# ATSAM4LC8C device description
Architecture: CORTEX-M4; Family: SAM4; Series: SAM4L
Registers are 32-bit, read-write, reset 0x0 unless marked. A register's access mark holds for its fields unless they carry their own. Offsets are from the block's base; [hi:lo] are bit positions; 'fields as' and 'values as' point back to an identical list.

## IISC — Inter-IC Sound (I2S) Controller
Instances: IISC 0x40004000
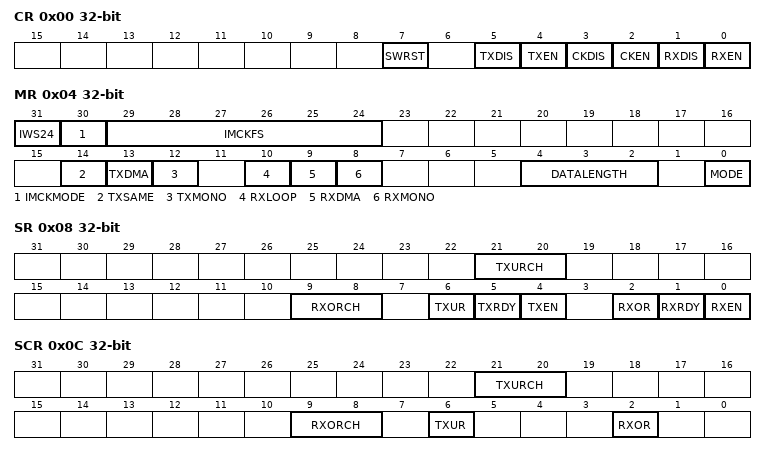
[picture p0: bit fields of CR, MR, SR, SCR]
0x00 CR wo reset not defined — Control Register
  [7] SWRST — Software Reset
    0=OFF (No effect); 1=ON (Performs a software reset. Has priority on any other bit in CR)
  [5] TXDIS — Transmit Disable
    0=OFF (No effect); 1=ON (Disables Data Transmit)
  [4] TXEN — Transmit Enable
    0=OFF (No effect); 1=ON (Enables Data Transmit if TXDIS is not set)
  [3] CKDIS — Clocks Disable
    0=OFF (No effect); 1=ON (Disables clocks)
  [2] CKEN — Clocks Enable
    0=OFF (No effect); 1=ON (Enables clocks if CKDIS is not set)
  [1] RXDIS — Receive Disable
    0=OFF (No effect); 1=ON (Disables Data Receive)
  [0] RXEN — Receive Enable
    0=OFF (No effect); 1=ON (Enables Data Receive if RXDIS is not set)
0x04 MR — Mode Register
  [31] IWS24 — IWS Data Slot Width
    0=IWS Data Slot is 32-bit wide for DATALENGTH=18/20/24-bit; 1=IWS Data Slot is 24-bit wide for DATALENGTH=18/20/24-bit
  [30] IMCKMODE — Master Clock Mode
    0=NO_IMCK (No IMCK generated); 1=IMCK (IMCK generated)
  [29:24] IMCKFS — Master Clock to fs Ratio
    0=16 fs; 1=32 fs; 3=64 fs; 7=128 fs; 15=256 fs; 23=384 fs; 31=512 fs; 47=768 fs; 63=1024 fs
  [14] TXSAME — Transmit Data when Underrun
    0=ZERO (Zero data transmitted in case of underrun); 1=SAME (Last data transmitted in case of underrun)
  [13] TXDMA — Single or Multiple DMA Channels for Transmitter
    0=SINGLE (Single DMA channel); 1=MULTIPLE (One DMA channel per data channel)
  [12] TXMONO — Transmitter Mono
    0=STEREO (Normal mode); 1=MONO (Left channel data is duplicated to right channel)
  [10] RXLOOP — Loop-back Test Mode
    0=OFF (Normal mode); 1=ON (ISDO internally connected to ISDI)
  [9] RXDMA — Single or Multiple DMA Channels for Receiver
    values as TXDMA
  [8] RXMONO — Receiver Mono
    values as TXMONO
  [4:2] DATALENGTH — Data Word Length
    0=32 bits; 1=24 bits; 2=20 bits; 3=18 bits; 4=16 bits; 5=16C (16 bits compact stereo); 6=8 bits; 7=8C (8 bits compact stereo)
  [0] MODE — Master/Slave/Controller Mode
    0=SLAVE (Slave mode (only serial data handled, clocks received from external master or controller)); 1=MASTER (Master mode (clocks generated and output by IISC, serial data handled if CR.RXEN and/or CR.TXEN written to 1))
0x08 SR ro — Status Register
  [21:20] TXURCH — Transmit Underrun Channels
    0=LEFT (Underrun first occurred on left channel); 1=RIGHT (Underrun first occurred on right channel)
  [9:8] RXORCH — Receive Overrun Channels
    0=LEFT (Overrun first occurred on left channel); 1=RIGHT (Overrun first occurred on right channel)
  [6] TXUR — Transmit Underrun
    0=NO (No underrun); 1=YES (The last bit of the last data written to the register THR has been set. Until the next write to THR, data will be sent according to MR.TXSAME field)
  [5] TXRDY — Transmit Ready
    0=FULL (The register THR is full and can't be written); 1=EMPTY (The register THR is empty and is ready to be written)
  [4] TXEN — Transmit Enable
    0=OFF (Transmitter is effectively disabled, following a CR.TXDIS or CR.SWRST request); 1=ON (Transmitter is effectively enabled, following a CR.TXEN request)
  [2] RXOR — Receive Overrun
    0=NO (No overrun); 1=YES (The previous received data has not been read. This data is lost)
  [1] RXRDY — Receive Ready
    0=EMPTY (The register RHR is empty and can't be read); 1=FULL (The register RHR is full and is ready to be read)
  [0] RXEN — Receive Enable
    0=OFF (Receiver is effectively disabled, following a CR.RXDIS or CR.SWRST request); 1=ON (Receiver is effectively enabled, following a CR.RXEN request)
0x0C SCR wo reset not defined (atomic clear of SR) — Status Clear Register
  [21:20] TXURCH — Transmit Underrun Channels
  [9:8] RXORCH — Receive Overrun Channels
  [6] TXUR — Transmit Underrun
    0=NO (No effect); 1=CLEAR (Clears the corresponding SR bit)
  [2] RXOR — Receive Overrun
    0=NO (No effect); 1=CLEAR (Clears the corresponding SR bit)
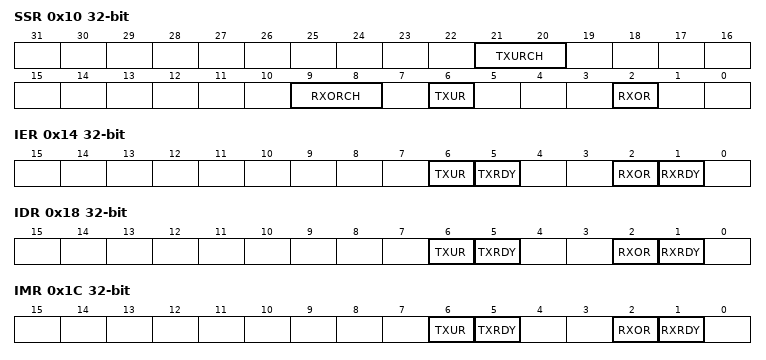
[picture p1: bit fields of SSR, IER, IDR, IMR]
0x10 SSR wo reset not defined (atomic set of SR) — Status Set Register
  [21:20] TXURCH — Transmit Underrun Channels
  [9:8] RXORCH — Receive Overrun Channels
  [6] TXUR — Transmit Underrun
    0=NO (No effect); 1=SET (Sets corresponding SR bit)
  [2] RXOR — Receive Overrun
    0=NO (No effect); 1=SET (Sets corresponding SR bit)
0x14 IER wo reset not defined (atomic set of IMR) — Interrupt Enable Register
  [all] fields
    0=OFF (No effect); 1=ON (Enables the corresponding interrupt)
  [6] TXUR — Transmit Underrun Interrupt Enable
  [5] TXRDY — Transmit Ready Interrupt Enable
  [2] RXOR — Receive Overrun Interrupt Enable
  [1] RXRDY — Receiver Ready Interrupt Enable
0x18 IDR wo reset not defined (atomic clear of IMR) — Interrupt Disable Register
  [all] fields
    0=OFF (No effect); 1=ON (Disables the corresponding interrupt)
  [6] TXUR — Transmit Underrun Interrupt Disable
  [5] TXRDY — Transmit Ready Interrupt Disable
  [2] RXOR — Receive Overrun Interrupt Disable
  [1] RXRDY — Receive Ready Interrupt Disable
0x1C IMR ro — Interrupt Mask Register
  [all] fields
    0=DISABLED (The corresponding interrupt is disabled); 1=ENABLED (The corresponding interrupt is enabled)
  [6] TXUR — Transmit Underrun Interrupt Mask
  [5] TXRDY — Transmit Ready Interrupt Mask
  [2] RXOR — Receive Overrun Interrupt Mask
  [1] RXRDY — Receive Ready Interrupt Mask
0x20 RHR ro — Receive Holding Register
  [31:0] RDAT — Receive Data
0x24 THR wo reset not defined — Transmit Holding Register
  [31:0] TDAT — Transmit Data
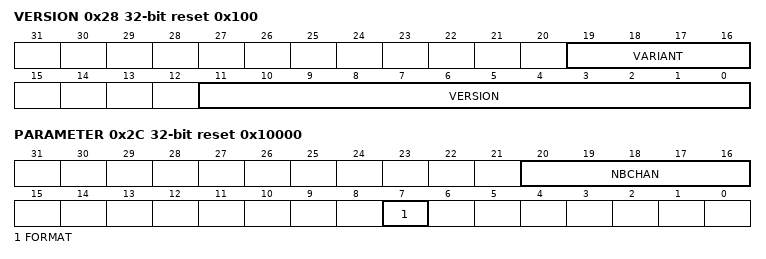
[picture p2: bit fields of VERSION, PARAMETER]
0x28 VERSION ro reset 0x100
  [19:16] VARIANT — Reserved. Value subject to change. No functionality associated.
  [11:0] VERSION — Reserved. Value subject to change. No functionality associated. This is the Atmel internal version of the macrocell.
0x2C PARAMETER ro reset 0x10000
  [20:16] NBCHAN — Maximum number of channels - 1
  [7] FORMAT — Data protocol format
    0=I2S (I2S format, stereo with IWS low for left channel)
